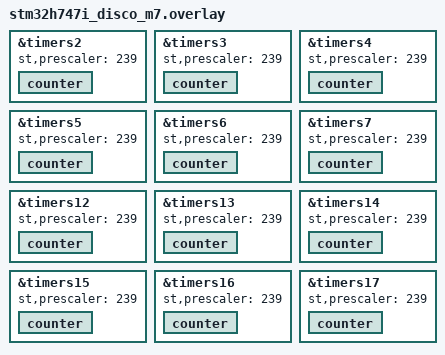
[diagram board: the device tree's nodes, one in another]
&timers2 {
	st,prescaler = <239>;
	counter {
		status = "okay";
	};
};

&timers3 {
	st,prescaler = <239>;
	counter {
		status = "okay";
	};
};

&timers4 {
	st,prescaler = <239>;
	counter {
		status = "okay";
	};
};

&timers5 {
	st,prescaler = <239>;
	counter {
		status = "okay";
	};
};

&timers6 {
	st,prescaler = <239>;
	counter {
		status = "okay";
	};
};

&timers7 {
	st,prescaler = <239>;
	counter {
		status = "okay";
	};
};

&timers12 {
	st,prescaler = <239>;
	counter {
		status = "okay";
	};
};

&timers13 {
	st,prescaler = <239>;
	counter {
		status = "okay";
	};
};

&timers14 {
	st,prescaler = <239>;
	counter {
		status = "okay";
	};
};

&timers15 {
	st,prescaler = <239>;
	counter {
		status = "okay";
	};
};

&timers16 {
	st,prescaler = <239>;
	counter {
		status = "okay";
	};
};

&timers17 {
	st,prescaler = <239>;
	counter {
		status = "okay";
	};
};
